# EVE1_SMSET register map
Vendor: Texas Instruments
Peripheral module from a debugger description file (folder DRA74xP_75xP_76xP_77xP).
Registers are 32-bit, read-write, reset 0x0 unless marked. A register's access mark holds for its fields unless they carry their own. Offsets are as the file gives them; lines under a group give offsets from that group; [hi:lo] are bit positions; {n}, {i} and the like mark numbered series; 'fields as' and 'values as' point back to an identical list; <NAME> marks a mode.

## EVE1_SMSET
0x00 SMSET_ID ro reset not defined — SMSET identification register
  [31:0] REVISION
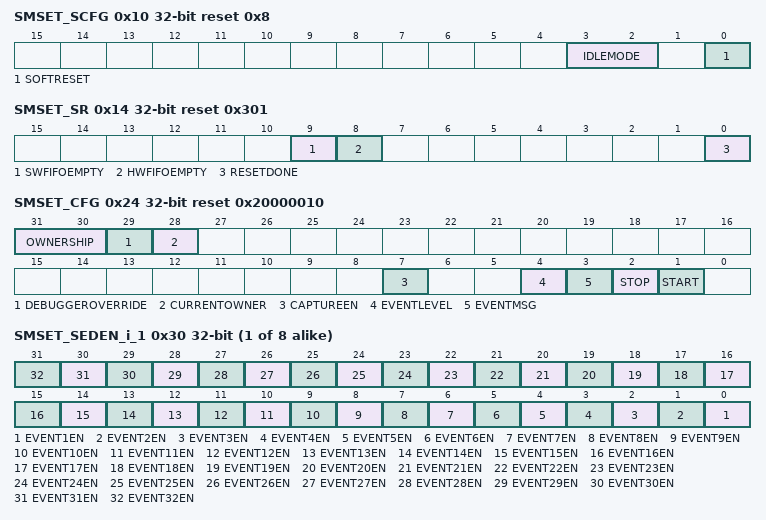
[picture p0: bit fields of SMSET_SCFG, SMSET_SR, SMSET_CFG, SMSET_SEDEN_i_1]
0x10 SMSET_SCFG access per field reset 0x8 — SMSET system configuration register
  [3:2] IDLEMODE ro — Configuration of the local target state management mode. 0x0: Force-idle; 0x1No-idle; 0x2 Smart-idle; 0x3 Smart-Idle wakeup-capable
  [0] SOFTRESET rw — Triggers System Event Trace module reset. This bit is automatically cleared by hardware
0x14 SMSET_SR ro reset 0x301 — SMSET Status Register
  [9] SWFIFOEMPTY — SW message FIFO empty
  [8] HWFIFOEMPTY — System event trace FIFO empty
  [0] RESETDONE — Reset completed
0x24 SMSET_CFG access per field reset 0x20000010 — SMSET Configuration register
  [31:30] OWNERSHIP rw — Read to get current ownership status. The claim status encoding is (0=Available, 1=Claimed, 2=Enabled, 3=Reserved);Send command to modify ownership state: 00= Release ownership, 01 = Claim ownership, 10 = Enable unit, 11 = No operation
  [29] DEBUGGEROVERRIDE rw — Reading from the DebuggerOverride bit returns a 1.
  [28] CURRENTOWNER ro — This value reflects the SMSET ownership when the register is in a non-Available state.
  [7] CAPTUREEN rw — When high the sytem event capture is enabled
  [4] EVENTLEVEL rw — This applies to all selected events: 0x0: low level event detection 0x1: high level evnet detection
  [3] EVENTMSG rw — essage generated based on: 0x0: sampling window 0x1: event detection
  [2] STOP rw — Stop capturing system events from external trigger detection [EMU1 HIGH to LOW]
  [1] START rw — Start capturing system events from external trigger detection [EMU0 HIGH to LOW]
0x28 SMSET_SESW access per field — System Event Sampling Window register
  [7:0] SAMPLINGWINDOWSIZE rw — System events sampling window size expressed as SMSET cycles
{0x2C+4i} SMSET_SEDEN_i_{i} (i=1..8) — System Event Detection Enable register 1
  [n-1] EVENT{n}EN (n=1..32) — Event {n} detection enable
